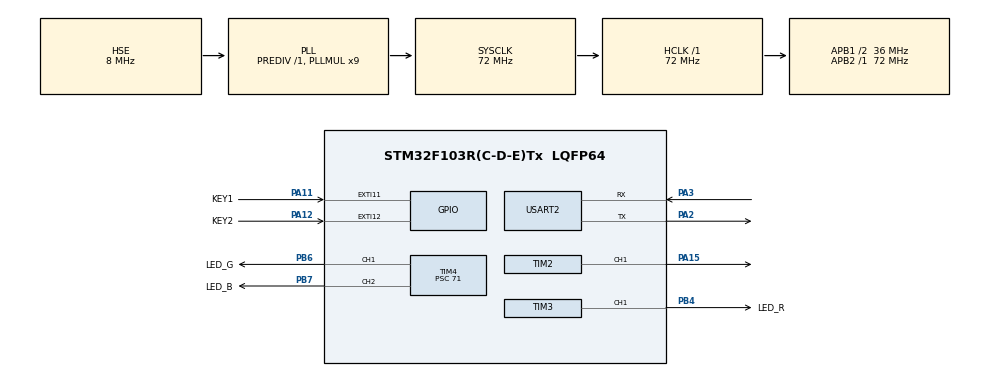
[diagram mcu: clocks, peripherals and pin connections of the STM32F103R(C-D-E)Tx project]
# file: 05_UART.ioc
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Mcu.Family=STM32F1
Mcu.Name=STM32F103R(C-D-E)Tx
Mcu.Package=LQFP64
NVIC.PriorityGroup=NVIC_PRIORITYGROUP_4
NVIC.USART2_IRQn=true\:0\:0\:false\:false\:true\:true\:true\:true
PA11.GPIO_Label=KEY1
PA11.GPIO_ModeDefaultEXTI=GPIO_MODE_IT_RISING_FALLING
PA11.GPIO_PuPd=GPIO_PULLUP
PA11.Signal=GPXTI11
PA12.GPIO_Label=KEY2
PA12.GPIO_ModeDefaultEXTI=GPIO_MODE_IT_RISING_FALLING
PA12.GPIO_PuPd=GPIO_PULLUP
PA12.Signal=GPXTI12
PA13.Mode=Serial_Wire
PA13.Signal=SYS_JTMS-SWDIO
PA14.Mode=Serial_Wire
PA14.Signal=SYS_JTCK-SWCLK
PA15.GPIO_Speed=GPIO_SPEED_FREQ_HIGH
PA15.Signal=S_TIM2_CH1_ETR
PA2.Mode=Asynchronous
PA2.Signal=USART2_TX
PA3.Mode=Asynchronous
PA3.Signal=USART2_RX
PB4.GPIO_Label=LED_R
PB4.GPIO_Speed=GPIO_SPEED_FREQ_HIGH
PB4.Signal=S_TIM3_CH1
PB6.GPIO_Label=LED_G
PB6.GPIO_Speed=GPIO_SPEED_FREQ_HIGH
PB6.Signal=S_TIM4_CH1
PB7.GPIO_Label=LED_B
PB7.GPIO_Speed=GPIO_SPEED_FREQ_HIGH
PB7.Signal=S_TIM4_CH2
PD0-OSC_IN.Mode=HSE-External-Oscillator
PD0-OSC_IN.Signal=RCC_OSC_IN
PD1-OSC_OUT.Mode=HSE-External-Oscillator
PD1-OSC_OUT.Signal=RCC_OSC_OUT
ProjectManager.HeapSize=0x200
ProjectManager.StackSize=0x400
ProjectManager.TargetToolchain=MDK-ARM V5.32
RCC.AHBFreq_Value=72000000
RCC.APB1CLKDivider=RCC_HCLK_DIV2
RCC.APB1Freq_Value=36000000
RCC.APB1TimFreq_Value=72000000
RCC.APB2Freq_Value=72000000
RCC.APB2TimFreq_Value=72000000
RCC.HCLKFreq_Value=72000000
RCC.PLLMUL=RCC_PLL_MUL9
RCC.PLLSourceVirtual=RCC_PLLSOURCE_HSE
RCC.SYSCLKFreq_VALUE=72000000
RCC.SYSCLKSource=RCC_SYSCLKSOURCE_PLLCLK
RCC.USBFreq_Value=72000000
SH.S_TIM2_CH1_ETR.0=TIM2_CH1,PWM Generation1 CH1
SH.S_TIM3_CH1.0=TIM3_CH1,PWM Generation1 CH1
SH.S_TIM4_CH1.0=TIM4_CH1,PWM Generation1 CH1
SH.S_TIM4_CH2.0=TIM4_CH2,PWM Generation2 CH2
TIM1.AutoReloadPreload=TIM_AUTORELOAD_PRELOAD_ENABLE
TIM1.Period=9999
TIM1.Prescaler=71
TIM2.Channel-PWM\ Generation1\ CH1=TIM_CHANNEL_1
TIM2.OCPolarity_1=TIM_OCPOLARITY_LOW
TIM2.Period=99
TIM2.Prescaler=71
TIM3.AutoReloadPreload=TIM_AUTORELOAD_PRELOAD_ENABLE
TIM3.Channel-PWM\ Generation1\ CH1=TIM_CHANNEL_1
TIM3.OCPolarity_1=TIM_OCPOLARITY_LOW
TIM3.Period=4999
TIM3.Prescaler=71
TIM4.AutoReloadPreload=TIM_AUTORELOAD_PRELOAD_ENABLE
TIM4.Channel-PWM\ Generation1\ CH1=TIM_CHANNEL_1
TIM4.Channel-PWM\ Generation2\ CH2=TIM_CHANNEL_2
TIM4.OCPolarity_1=TIM_OCPOLARITY_LOW
TIM4.OCPolarity_2=TIM_OCPOLARITY_LOW
TIM4.Period=4999
TIM4.Prescaler=71
USART2.VirtualMode=VM_ASYNC
VP_TIM1_VS_ClockSourceINT.Mode=Internal
VP_TIM2_VS_ClockSourceINT.Mode=Internal
VP_TIM3_VS_ClockSourceINT.Mode=Internal
VP_TIM4_VS_ClockSourceINT.Mode=Internal
board=custom

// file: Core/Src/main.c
/* USER CODE BEGIN Header */
/**
  ******************************************************************************
  * @file           : main.c
  * @brief          : Main program body
  ******************************************************************************
  * @attention
  *
  * Copyright (c) 2025 STMicroelectronics.
  * All rights reserved.
  *
  * This software is licensed under terms that can be found in the LICENSE file
  * in the root directory of this software component.
  * If no LICENSE file comes with this software, it is provided AS-IS.
  *
  ******************************************************************************
  */
/* USER CODE END Header */
#include "main.h"
#include "tim.h"
#include "usart.h"
#include "gpio.h"

/* USER CODE BEGIN PV */
uint8_t uartSendData[] = "sesame\r\n";
uint8_t uartRxData = 0;

/* USER CODE END PV */

void SystemClock_Config(void);

int main(void)
{

  /* MCU Configuration--------------------------------------------------------*/

  /* Reset of all peripherals, Initializes the Flash interface and the Systick. */
  HAL_Init();

  /* Configure the system clock */
  SystemClock_Config();

  /* Initialize all configured peripherals */
  MX_GPIO_Init();
  MX_TIM1_Init();
  MX_TIM3_Init();
  MX_TIM4_Init();
  MX_TIM2_Init();
  MX_USART2_UART_Init();
  /* USER CODE BEGIN 2 */
  HAL_UART_Receive_IT(&huart2,&uartRxData,1);
  /* USER CODE END 2 */

  /* Infinite loop */
  /* USER CODE BEGIN WHILE */
  while (1)
  {
    // HAL_UART_Transmit(&huart2,uartSendData,sizeof(uartSendData),0xffff);
    // HAL_Delay(500);
    /* USER CODE END WHILE */

  }
}

void SystemClock_Config(void)
{
  RCC_OscInitTypeDef RCC_OscInitStruct = {0};
  RCC_ClkInitTypeDef RCC_ClkInitStruct = {0};

  /** Initializes the RCC Oscillators according to the specified parameters
  * in the RCC_OscInitTypeDef structure.
  */
  RCC_OscInitStruct.OscillatorType = RCC_OSCILLATORTYPE_HSE;
  RCC_OscInitStruct.HSEState = RCC_HSE_ON;
  RCC_OscInitStruct.HSEPredivValue = RCC_HSE_PREDIV_DIV1;
  RCC_OscInitStruct.HSIState = RCC_HSI_ON;
  RCC_OscInitStruct.PLL.PLLState = RCC_PLL_ON;
  RCC_OscInitStruct.PLL.PLLSource = RCC_PLLSOURCE_HSE;
  RCC_OscInitStruct.PLL.PLLMUL = RCC_PLL_MUL9;
  if (HAL_RCC_OscConfig(&RCC_OscInitStruct) != HAL_OK)
  {
    Error_Handler();
  }

  /** Initializes the CPU, AHB and APB buses clocks
  */
  RCC_ClkInitStruct.ClockType = RCC_CLOCKTYPE_HCLK|RCC_CLOCKTYPE_SYSCLK
                              |RCC_CLOCKTYPE_PCLK1|RCC_CLOCKTYPE_PCLK2;
  RCC_ClkInitStruct.SYSCLKSource = RCC_SYSCLKSOURCE_PLLCLK;
  RCC_ClkInitStruct.AHBCLKDivider = RCC_SYSCLK_DIV1;
  RCC_ClkInitStruct.APB1CLKDivider = RCC_HCLK_DIV2;
  RCC_ClkInitStruct.APB2CLKDivider = RCC_HCLK_DIV1;

  if (HAL_RCC_ClockConfig(&RCC_ClkInitStruct, FLASH_LATENCY_2) != HAL_OK)
  {
    Error_Handler();
  }
}

/* USER CODE BEGIN 4 */
void HAL_UART_RxCpltCallback(UART_HandleTypeDef *huart)
{
  if(huart == &huart2)
  {
    HAL_UART_Transmit(&huart2,&uartRxData,1,0xffff);
    HAL_UART_Receive_IT(&huart2,&uartRxData,1);
  }

}
/* USER CODE END 4 */

void Error_Handler(void)
{
  __disable_irq();
  while (1)
  {
  }
}
